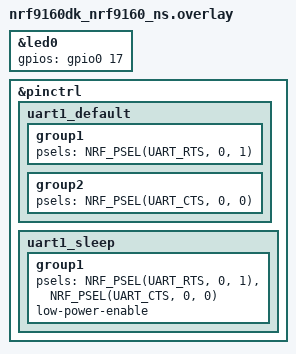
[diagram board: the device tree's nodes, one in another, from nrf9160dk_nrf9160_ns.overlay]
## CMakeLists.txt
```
#
# Copyright (c) 2020 Nordic Semiconductor
#
# SPDX-License-Identifier: LicenseRef-Nordic-5-Clause
#

cmake_minimum_required(VERSION 3.20.0)

find_package(Zephyr REQUIRED HINTS $ENV{ZEPHYR_BASE})
project(nrf9160-Recreation)

# NORDIC SDK APP START
target_sources(app PRIVATE src/main.c)
target_sources(app PRIVATE src/saadc.c)

# NORDIC SDK APP END

zephyr_include_directories(src)

# Make folder containing certificates global so that it can be located by
# the AWS IoT library.
zephyr_include_directories_ifdef(CONFIG_AWS_IOT_PROVISION_CERTIFICATES certs)

target_include_directories(app PRIVATE ../hal_nordic-master/nrfx/samples/common ../hal_nordic-master/nrfx/samples/src/nrfx_saadc/common)
```

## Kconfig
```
#
# Copyright (c) 2020 Nordic Semiconductor ASA
#
# SPDX-License-Identifier: LicenseRef-Nordic-5-Clause
#

menu "AWS IoT Sample Settings"

config AWS_IOT_SAMPLE_APP_VERSION
	string "Application version"
	default "v1.0.0"

config AWS_IOT_SAMPLE_PUBLICATION_INTERVAL_SECONDS
	int "Interval in seconds that the sample will publish data"
	default 15

config AWS_IOT_SAMPLE_CONNECTION_RETRY_TIMEOUT_SECONDS
	int "Number of seconds between each AWS IoT connection retry"
	default 30

config AWS_IOT_SAMPLE_DEVICE_ID_USE_HW_ID
	bool "Use HW ID as device ID"
	select HW_ID_LIBRARY
	help
	  Use the devices's hardware ID as device ID when connecting to AWS IOT

module = AWS_IOT_SAMPLE
module-str = AWS IoT sample
source "${ZEPHYR_BASE}/subsys/logging/Kconfig.template.log_config"

endmenu

menu "Zephyr Kernel"
source "Kconfig.zephyr"
endmenu
```

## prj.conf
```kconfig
#
# Copyright (c) 2020 Nordic Semiconductor ASA
#
# SPDX-License-Identifier: LicenseRef-Nordic-5-Clause
#
# General config
CONFIG_NCS_SAMPLES_DEFAULTS=y
CONFIG_REBOOT=y

# NEWLIB C
CONFIG_NEWLIB_LIBC=y
CONFIG_NEWLIB_LIBC_FLOAT_PRINTF=y

# Log
CONFIG_LOG=y
CONFIG_AWS_IOT_SAMPLE_LOG_LEVEL_INF=y
CONFIG_LOG_MODE_IMMEDIATE=y

# Network
CONFIG_NETWORKING=y
CONFIG_NET_NATIVE=n

# LTE link control
CONFIG_LTE_LINK_CONTROL=y
CONFIG_LTE_NETWORK_MODE_LTE_M=y

# Modem library
CONFIG_NRF_MODEM_LIB=y

# AT Host
CONFIG_UART_INTERRUPT_DRIVEN=y
CONFIG_AT_HOST_LIBRARY=y

# AWS IoT library
CONFIG_AWS_IOT=y
CONFIG_AWS_IOT_CLIENT_ID_STATIC="my-thing"
CONFIG_AWS_IOT_BROKER_HOST_NAME="a2eq7i1ma8qxed-ats.iot.us-east-2.amazonaws.com"
CONFIG_AWS_IOT_SEC_TAG=16842753
CONFIG_AWS_IOT_APP_SUBSCRIPTION_LIST_COUNT=2
CONFIG_AWS_IOT_TOPIC_UPDATE_DELTA_SUBSCRIBE=y
CONFIG_AWS_IOT_LAST_WILL=y
CONFIG_AWS_IOT_TOPIC_GET_ACCEPTED_SUBSCRIBE=y
CONFIG_AWS_IOT_TOPIC_GET_REJECTED_SUBSCRIBE=y

# MQTT - Maximum MQTT keepalive timeout specified by AWS IoT Core
CONFIG_MQTT_KEEPALIVE=1200

# Date Time library
CONFIG_DATE_TIME=y

# Modem information
CONFIG_MODEM_INFO=y

# Heap and stacks
CONFIG_HEAP_MEM_POOL_SIZE=8192
CONFIG_MAIN_STACK_SIZE=4096
CONFIG_SYSTEM_WORKQUEUE_STACK_SIZE=2048

# MCUBOOT
CONFIG_BOOTLOADER_MCUBOOT=y
CONFIG_MCUBOOT_IMG_MANAGER=y

# Image manager
CONFIG_IMG_MANAGER=y
CONFIG_STREAM_FLASH=y
CONFIG_FLASH_MAP=y
CONFIG_FLASH=y
CONFIG_IMG_ERASE_PROGRESSIVELY=y

# AWS FOTA
CONFIG_AWS_FOTA=y
CONFIG_FOTA_DOWNLOAD=y
CONFIG_DFU_TARGET=y

# CJSON
CONFIG_CJSON_LIB=y

# Download client (needed by AWS FOTA)
CONFIG_DOWNLOAD_CLIENT=y
CONFIG_DOWNLOAD_CLIENT_STACK_SIZE=4096

CONFIG_NRF_MODEM_LIB_TRACE=y
CONFIG_AT_HOST_LIBRARY=y #(note this is optional)

CONFIG_ADC=y
CONFIG_NRFX_GPIOTE=y
CONFIG_NRFX_SAADC=y
CONFIG_ASSERT=y
```

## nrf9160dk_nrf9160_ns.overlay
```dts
// To get started, press Ctrl+Space (or Option+Esc) to bring up the completion menu and view the available nodes.

// You can also use the buttons in the sidebar to perform actions on nodes.
// Actions currently available include:

// * Enabling / disabling the node
// * Adding the bus to a bus
// * Removing the node
// * Connecting ADC channels

// For more help, browse the DeviceTree documentation at https://docs.zephyrproject.org/latest/guides/dts/index.html
// You can also visit the nRF DeviceTree extension documentation at https://nrfconnect.github.io/vscode-nrf-connect/devicetree/nrfdevicetree.html
&led0 {
    gpios = <&gpio0 17 0 >;
};

&pinctrl {
    uart1_default {
        group1 {
            psels = <NRF_PSEL(UART_RTS, 0, 1)>;

        };
        group2 {
            psels = <NRF_PSEL(UART_CTS, 0, 0)>;
        };

    };

    uart1_sleep {
        group1 {
            psels = <NRF_PSEL(UART_RTS, 0, 1)>,
				<NRF_PSEL(UART_CTS, 0, 0)>; 
            low-power-enable;
        };
    };
};
```

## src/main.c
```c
/*
 * Copyright (c) 2020 Nordic Semiconductor ASA
 *
 * SPDX-License-Identifier: LicenseRef-Nordic-5-Clause
 */

#include <zephyr/kernel.h>
#include <stdio.h>
#include <stdlib.h>
#if defined(CONFIG_NRF_MODEM_LIB)
#include <modem/lte_lc.h>
#include <modem/nrf_modem_lib.h>
#include <modem/modem_info.h>
#include <nrf_modem.h>
#endif
#include <net/aws_iot.h>
#include <zephyr/sys/reboot.h>
#include <date_time.h>
#include <zephyr/dfu/mcuboot.h>
#include <cJSON.h>
#include <cJSON_os.h>
#include <zephyr/logging/log.h>
#if defined(CONFIG_AWS_IOT_SAMPLE_DEVICE_ID_USE_HW_ID)
#include <hw_id.h>
#endif

#define MAX_FLOAT_STR_SIZE 15

LOG_MODULE_REGISTER(aws_iot_sample, CONFIG_AWS_IOT_SAMPLE_LOG_LEVEL);

BUILD_ASSERT(!IS_ENABLED(CONFIG_LTE_AUTO_INIT_AND_CONNECT),
	     "This sample does not support LTE auto-init and connect");

#define APP_TOPICS_COUNT CONFIG_AWS_IOT_APP_SUBSCRIPTION_LIST_COUNT

static struct k_work_delayable shadow_update_work;
static struct k_work_delayable connect_work;
static struct k_work shadow_update_version_work;

static bool cloud_connected;

static K_SEM_DEFINE(lte_connected, 0, 1);
static K_SEM_DEFINE(date_time_obtained, 0, 1);

static int json_add_obj(cJSON *parent, const char *str, cJSON *item)
{
	cJSON_AddItemToObject(parent, str, item);

	return 0;
}

static int json_add_str(cJSON *parent, const char *str, const char *item)
{
	cJSON *json_str;

	json_str = cJSON_CreateString(item);
	if (json_str == NULL) {
		return -ENOMEM;
	}

	return json_add_obj(parent, str, json_str);
}

static int json_add_number(cJSON *parent, const char *str, double item)
{
	cJSON *json_num;

	json_num = cJSON_CreateNumber(item);
	if (json_num == NULL) {
		return -ENOMEM;
	}

	return json_add_obj(parent, str, json_num);
}

static int shadow_update(bool version_number_include)
{
	int err;
	char *message;
	int64_t message_ts = 0;
	float mV = 0;
	int raw = 0;

	LOG_INF("Getting date and time");
	err = date_time_now(&message_ts);
	if (err) {
		LOG_ERR("date_time_now, error: %d", err);
		return err;
	}
	LOG_INF("Trying to read from the ADC");
	err = get_adc_reading(&mV, &raw);
		if (err) {
		LOG_ERR("get_adc_reading, error: %d", err);
		return err;
	}
	char float_str[MAX_FLOAT_STR_SIZE];
	snprintf(float_str, MAX_FLOAT_STR_SIZE, "%f", mV);
	LOG_INF("Raw value == %d mV value == %s", raw, float_str);

	cJSON *root_obj = cJSON_CreateObject();
	cJSON *state_obj = cJSON_CreateObject();
	cJSON *reported_obj = cJSON_CreateObject();

	if (root_obj == NULL || state_obj == NULL || reported_obj == NULL) {
		cJSON_Delete(root_obj);
		cJSON_Delete(state_obj);
		cJSON_Delete(reported_obj);
		err = -ENOMEM;
		return err;
	}

	if (version_number_include) {
		err = json_add_str(reported_obj, "app_version", CONFIG_AWS_IOT_SAMPLE_APP_VERSION);
	} else {
		err = 0;
	}

	err += json_add_number(reported_obj, "raw", raw);
	err += json_add_number(reported_obj, "converted", mV);
	err += json_add_number(reported_obj, "ts", message_ts);
	err += json_add_obj(state_obj, "reported", reported_obj);
	err += json_add_obj(root_obj, "state", state_obj);

	if (err) {
		LOG_ERR("json_add, error: %d", err);
		goto cleanup;
	}

	message = cJSON_Print(root_obj);
	if (message == NULL) {
		LOG_ERR("cJSON_Print, error: returned NULL");
		err = -ENOMEM;
		goto cleanup;
	}

	struct aws_iot_data tx_data = {
		.qos = MQTT_QOS_0_AT_MOST_ONCE,
		.topic.type = AWS_IOT_SHADOW_TOPIC_UPDATE,
		.ptr = message,
		.len = strlen(message)
	};

	LOG_INF("Publishing: %s to AWS IoT broker", message);

	err = aws_iot_send(&tx_data);
	if (err) {
		LOG_ERR("aws_iot_send, error: %d", err);
	}

	cJSON_FreeString(message);

cleanup:

	cJSON_Delete(root_obj);

	return err;
}

static void connect_work_fn(struct k_work *work)
{
	int err;

	if (cloud_connected) {
		return;
	}

	err = aws_iot_connect(NULL);
	if (err) {
		LOG_ERR("aws_iot_connect, error: %d", err);
	}

	LOG_INF("Next connection retry in %d seconds",
		CONFIG_AWS_IOT_SAMPLE_CONNECTION_RETRY_TIMEOUT_SECONDS);

	k_work_schedule(&connect_work,
			K_SECONDS(CONFIG_AWS_IOT_SAMPLE_CONNECTION_RETRY_TIMEOUT_SECONDS));
}

static void shadow_update_work_fn(struct k_work *work)
{
	int err;

	if (!cloud_connected) {
		return;
	}

	err = shadow_update(false);
	if (err) {
		LOG_ERR("shadow_update, error: %d", err);
	}

	LOG_INF("Next data publication in %d seconds",
		CONFIG_AWS_IOT_SAMPLE_PUBLICATION_INTERVAL_SECONDS);

	k_work_schedule(&shadow_update_work,
			K_SECONDS(CONFIG_AWS_IOT_SAMPLE_PUBLICATION_INTERVAL_SECONDS));
}

static void shadow_update_version_work_fn(struct k_work *work)
{
	int err;

	err = shadow_update(true);
	if (err) {
		LOG_ERR("shadow_update, error: %d", err);
	}
}

static void print_received_data(const char *buf, const char *topic,
				size_t topic_len)
{
	char *str = NULL;
	cJSON *root_obj = NULL;

	root_obj = cJSON_Parse(buf);
	if (root_obj == NULL) {
		LOG_ERR("cJSON Parse failure");
		return;
	}

	str = cJSON_Print(root_obj);
	if (str == NULL) {
		LOG_ERR("Failed to print JSON object");
		goto clean_exit;
	}

	LOG_INF("Data received from AWS IoT console: Topic: %.*s Message: %s",
		topic_len, topic, str);

	cJSON_FreeString(str);

clean_exit:
	cJSON_Delete(root_obj);
}

void aws_iot_event_handler(const struct aws_iot_evt *const evt)
{
	switch (evt->type) {
	case AWS_IOT_EVT_CONNECTING:
		LOG_INF("AWS_IOT_EVT_CONNECTING");
		break;
	case AWS_IOT_EVT_CONNECTED:
		LOG_INF("AWS_IOT_EVT_CONNECTED");

		cloud_connected = true;
		/* This may fail if the work item is already being processed,
		 * but in such case, the next time the work handler is executed,
		 * it will exit after checking the above flag and the work will
		 * not be scheduled again.
		 */
		(void)k_work_cancel_delayable(&connect_work);

		if (evt->data.persistent_session) {
			LOG_INF("Persistent session enabled");
		}

#if defined(CONFIG_NRF_MODEM_LIB)
		/** Successfully connected to AWS IoT broker, mark image as
		 *  working to avoid reverting to the former image upon reboot.
		 */
		boot_write_img_confirmed();
#endif

		/** Send version number to AWS IoT broker to verify that the
		 *  FOTA update worked.
		 */
		k_work_submit(&shadow_update_version_work);

		/** Start sequential shadow data updates.
		 */
		k_work_schedule(&shadow_update_work,
				K_SECONDS(CONFIG_AWS_IOT_SAMPLE_PUBLICATION_INTERVAL_SECONDS));

#if defined(CONFIG_NRF_MODEM_LIB)
		int err = lte_lc_psm_req(true);
		if (err) {
			LOG_ERR("Requesting PSM failed, error: %d", err);
		}
#endif
		break;
	case AWS_IOT_EVT_READY:
		LOG_INF("AWS_IOT_EVT_READY");
		break;
	case AWS_IOT_EVT_DISCONNECTED:
		LOG_INF("AWS_IOT_EVT_DISCONNECTED");
		cloud_connected = false;
		/* This may fail if the work item is already being processed,
		 * but in such case, the next time the work handler is executed,
		 * it will exit after checking the above flag and the work will
		 * not be scheduled again.
		 */
		(void)k_work_cancel_delayable(&shadow_update_work);
		k_work_schedule(&connect_work, K_NO_WAIT);
		break;
	case AWS_IOT_EVT_DATA_RECEIVED:
		LOG_INF("AWS_IOT_EVT_DATA_RECEIVED");
		print_received_data(evt->data.msg.ptr, evt->data.msg.topic.str,
				    evt->data.msg.topic.len);
		break;
	case AWS_IOT_EVT_PUBACK:
		LOG_INF("AWS_IOT_EVT_PUBACK, message ID: %d", evt->data.message_id);
		break;
	case AWS_IOT_EVT_FOTA_START:
		LOG_INF("AWS_IOT_EVT_FOTA_START");
		break;
	case AWS_IOT_EVT_FOTA_ERASE_PENDING:
		LOG_INF("AWS_IOT_EVT_FOTA_ERASE_PENDING");
		LOG_INF("Disconnect LTE link or reboot");
#if defined(CONFIG_NRF_MODEM_LIB)
		err = lte_lc_offline();
		if (err) {
			LOG_ERR("Error disconnecting from LTE");
		}
#endif
		break;
	case AWS_IOT_EVT_FOTA_ERASE_DONE:
		LOG_INF("AWS_FOTA_EVT_ERASE_DONE");
		LOG_INF("Reconnecting the LTE link");
#if defined(CONFIG_NRF_MODEM_LIB)
		err = lte_lc_connect();
		if (err) {
			LOG_ERR("Error connecting to LTE");
		}
#endif
		break;
	case AWS_IOT_EVT_FOTA_DONE:
		LOG_INF("AWS_IOT_EVT_FOTA_DONE");
		LOG_INF("FOTA done, rebooting device");
		aws_iot_disconnect();
		sys_reboot(0);
		break;
	case AWS_IOT_EVT_FOTA_DL_PROGRESS:
		LOG_INF("AWS_IOT_EVT_FOTA_DL_PROGRESS, (%d%%)", evt->data.fota_progress);
	case AWS_IOT_EVT_ERROR:
		LOG_INF("AWS_IOT_EVT_ERROR, %d", evt->data.err);
		break;
	case AWS_IOT_EVT_FOTA_ERROR:
		LOG_INF("AWS_IOT_EVT_FOTA_ERROR");
		break;
	default:
		LOG_WRN("Unknown AWS IoT event type: %d", evt->type);
		break;
	}
}

static void work_init(void)
{
	k_work_init_delayable(&shadow_update_work, shadow_update_work_fn);
	k_work_init_delayable(&connect_work, connect_work_fn);
	k_work_init(&shadow_update_version_work, shadow_update_version_work_fn);
}

#if defined(CONFIG_NRF_MODEM_LIB)
static void lte_handler(const struct lte_lc_evt *const evt)
{
	switch (evt->type) {
	case LTE_LC_EVT_NW_REG_STATUS:
		if ((evt->nw_reg_status != LTE_LC_NW_REG_REGISTERED_HOME) &&
		     (evt->nw_reg_status != LTE_LC_NW_REG_REGISTERED_ROAMING)) {
			break;
		}

		LOG_INF("Network registration status: %s",
			evt->nw_reg_status == LTE_LC_NW_REG_REGISTERED_HOME ?
			"Connected - home network" : "Connected - roaming");

		k_sem_give(&lte_connected);
		break;
	case LTE_LC_EVT_PSM_UPDATE:
		LOG_INF("PSM parameter update: TAU: %d, Active time: %d",
			evt->psm_cfg.tau, evt->psm_cfg.active_time);
		break;
	case LTE_LC_EVT_EDRX_UPDATE: {
		char log_buf[60];
		ssize_t len;

		len = snprintf(log_buf, sizeof(log_buf),
			       "eDRX parameter update: eDRX: %f, PTW: %f",
			       evt->edrx_cfg.edrx, evt->edrx_cfg.ptw);
		if (len > 0) {
			LOG_INF("%s", log_buf);
		}
		break;
	}
	case LTE_LC_EVT_RRC_UPDATE:
		LOG_INF("RRC mode: %s",
			evt->rrc_mode == LTE_LC_RRC_MODE_CONNECTED ?
			"Connected" : "Idle");
		break;
	case LTE_LC_EVT_CELL_UPDATE:
		LOG_INF("LTE cell changed: Cell ID: %d, Tracking area: %d",
			evt->cell.id, evt->cell.tac);
		break;
	default:
		break;
	}
}

static void nrf_modem_lib_dfu_handler(int err)
{
	switch (err) {
	case NRF_MODEM_DFU_RESULT_OK:
		LOG_INF("Modem update suceeded, reboot");
		sys_reboot(SYS_REBOOT_COLD);
		break;
	case NRF_MODEM_DFU_RESULT_UUID_ERROR:
	case NRF_MODEM_DFU_RESULT_AUTH_ERROR:
		LOG_INF("Modem update failed, error: %d", err);
		LOG_INF("Modem will use old firmware");
		sys_reboot(SYS_REBOOT_COLD);
		break;
	case NRF_MODEM_DFU_RESULT_HARDWARE_ERROR:
	case NRF_MODEM_DFU_RESULT_INTERNAL_ERROR:
		LOG_INF("Modem update malfunction, error: %d, reboot", err);
		sys_reboot(SYS_REBOOT_COLD);
		break;
	case NRF_MODEM_DFU_RESULT_VOLTAGE_LOW:
		LOG_INF("Modem update cancelled due to low power, error: %d", err);
		LOG_INF("Please reboot once you have sufficient power for the DFU");
		break;
	default:
		break;
	}
}
#endif

static int app_topics_subscribe(void)
{
	int err;
	static char custom_topic[75] = "my-custom-topic/example";
	static char custom_topic_2[75] = "my-custom-topic/example_2";

	const struct aws_iot_topic_data topics_list[APP_TOPICS_COUNT] = {
		[0].str = custom_topic,
		[0].len = strlen(custom_topic),
		[1].str = custom_topic_2,
		[1].len = strlen(custom_topic_2)
	};

	err = aws_iot_subscription_topics_add(topics_list, ARRAY_SIZE(topics_list));
	if (err) {
		LOG_ERR("aws_iot_subscription_topics_add, error: %d", err);
	}

	return err;
}

static void date_time_event_handler(const struct date_time_evt *evt)
{
	switch (evt->type) {
	case DATE_TIME_OBTAINED_MODEM:
		/* Fall through */
	case DATE_TIME_OBTAINED_NTP:
		/* Fall through */
	case DATE_TIME_OBTAINED_EXT:
		LOG_INF("Date time obtained");
		k_sem_give(&date_time_obtained);

		/* De-register handler. At this point the sample will have
		 * date time to depend on indefinitely until a reboot occurs.
		 */
		date_time_register_handler(NULL);
		break;
	case DATE_TIME_NOT_OBTAINED:
		LOG_INF("DATE_TIME_NOT_OBTAINED");
		break;
	default:
		LOG_ERR("Unknown event: %d", evt->type);
		break;
	}
}

int main(void)
{
	int err;

	LOG_INF("The nRF9160 Recreation started");

	cJSON_Init();

#if defined(CONFIG_NRF_MODEM_LIB)
	err = nrf_modem_lib_init();
	if (err) {
		LOG_ERR("Modem library initialization failed, error: %d", err);
		return 0;
	}

	nrf_modem_lib_dfu_handler(err);
#endif

#if defined(CONFIG_AWS_IOT_SAMPLE_DEVICE_ID_USE_HW_ID)
	char device_id[HW_ID_LEN] = { 0 };

	err = hw_id_get(device_id, ARRAY_SIZE(device_id));
	if (err) {
		LOG_ERR("Failed to retrieve device ID, error: %d", err);
		return 0;
	}

	struct aws_iot_config config = {
	    .client_id = device_id,
	    .client_id_len = strlen(device_id)
	};

	LOG_INF("Device id: %s", device_id);

	err = aws_iot_init(&config, aws_iot_event_handler);
#else
	err = aws_iot_init(NULL, aws_iot_event_handler);
#endif
	if (err) {
		LOG_ERR("AWS IoT library could not be initialized, error: %d", err);
	}

	/** Subscribe to customizable non-shadow specific topics
	 *  to AWS IoT backend.
	 */
	err = app_topics_subscribe();
	if (err) {
		LOG_ERR("Adding application specific topics failed, error: %d", err);
	}

	work_init();
#if defined(CONFIG_NRF_MODEM_LIB)
	err = lte_lc_init_and_connect_async(lte_handler);
	if (err) {
		LOG_ERR("Modem could not be configured, error: %d", err);
		return 0;
	}

	err = modem_info_init();
	if (err) {
		LOG_ERR("Failed initializing modem info module, error: %d", err);
	}

	k_sem_take(&lte_connected, K_FOREVER);
#endif

	/* Trigger a date time update. The date_time API is used to timestamp data that is sent
	 * to AWS IoT.
	 */
	date_time_update_async(date_time_event_handler);

	/* Postpone connecting to AWS IoT until date time has been obtained. */
	k_sem_take(&date_time_obtained, K_FOREVER);
	k_work_schedule(&connect_work, K_NO_WAIT);

	return 0;
}
```

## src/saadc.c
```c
#include <zephyr/kernel.h>
#include <zephyr/device.h>
#include <zephyr/drivers/gpio.h>
#include <zephyr/drivers/adc.h>
#include <stdio.h>
#include <string.h>
#include <nrfx_saadc.h>
#include <nrfx_gpiote.h>
#include <nrfx_example.h>
#include <saadc_examples_common.h>
#include <nrfx_log.h>


#define ADC_1ST_CHANNEL_INPUT NRF_SAADC_INPUT_AIN1
#define BUFFER_SIZE 2UL
#define SAMPLING_ITERATIONS 4UL
#define ADC_RESOLUTION NRF_SAADC_RESOLUTION_14BIT
#define ADC_GAIN ADC_GAIN_1_4
#define ADC_REFERENCE ADC_REF_VDD_1_4
#define ADC_ACQUISITION_TIME ADC_ACQ_TIME(ADC_ACQ_TIME_MICROSECONDS, 20)
#define SLEEP_TIME_MS 700
#define ADC_OVERSAMPLING SAADC_OVERSAMPLE_OVERSAMPLE_Over256x
#define VDD_GPIO 1800

static nrf_saadc_value_t m_samples_buffer[BUFFER_SIZE];

float custom_raw_to_milli(int raw) {
	//Hard coded values, change with Gain/Resolution Stuff
    float denominator = 0.00055556;  //.25/VDD_4
    int exponent = 16384; //2^RESOLUTION

    // Calculate [V(P) - V(N)]
    float voltageDifference = (raw / (denominator * exponent));

    return voltageDifference;
}

static const nrfx_saadc_channel_t nrf_1st_channel = {
	.channel_config = {
		.resistor_p = NRF_SAADC_RESISTOR_DISABLED,
		.resistor_n = NRF_SAADC_RESISTOR_DISABLED,
		.gain = ADC_GAIN,
		.reference = ADC_REFERENCE,
		.acq_time = ADC_ACQUISITION_TIME,
		.mode = NRF_SAADC_MODE_SINGLE_ENDED,
		.burst = NRF_SAADC_BURST_ENABLED,
	},
	.pin_p = ADC_1ST_CHANNEL_INPUT,
	.pin_n = NRF_SAADC_INPUT_DISABLED,
	.channel_index = 0
};

int get_adc_reading(float *milivolt, int *raw) {

	struct gpio_dt_spec p17 = GPIO_DT_SPEC_GET(DT_NODELABEL(led0), gpios);
	struct gpio_dt_spec led1 = GPIO_DT_SPEC_GET(DT_ALIAS(led1), gpios);

	if (!device_is_ready(p17.port)) return -1;
	if (!device_is_ready(led1.port)) return -1;

	nrfx_err_t status;
    (void)status;

	status = nrfx_saadc_init(NRFX_SAADC_DEFAULT_CONFIG_IRQ_PRIORITY);
    NRFX_ASSERT(status == NRFX_SUCCESS);


    status = nrfx_saadc_channel_config(&nrf_1st_channel);
    NRFX_ASSERT(status == NRFX_SUCCESS);

	nrfx_saadc_adv_config_t nrf_adv_1st_cfg = {
		.oversampling = ADC_OVERSAMPLING,
		.burst = NRF_SAADC_BURST_ENABLED,
	};

	uint32_t channel_mask = nrfx_saadc_channels_configured_get();
    status = nrfx_saadc_advanced_mode_set(channel_mask,
                                          ADC_RESOLUTION,
                                          &nrf_adv_1st_cfg,
                                          NULL);
    NRFX_ASSERT(status == NRFX_SUCCESS);

    status = nrfx_saadc_buffer_set(m_samples_buffer, BUFFER_SIZE);
    NRFX_ASSERT(status == NRFX_SUCCESS);

	status = nrfx_saadc_offset_calibrate(NULL);
	NRFX_ASSERT(status == NRFX_SUCCESS);
	printk("Calibration in the blocking manner finished successfully.\n");
	
	int err;
	gpio_pin_configure_dt(&p17, GPIO_OUTPUT);
	gpio_pin_configure_dt(&led1, GPIO_OUTPUT_ACTIVE);
	err = gpio_pin_set_dt(&p17, 1);
	err = gpio_pin_set_dt(&led1, 1);

	if (err) return err;
	
	int ret = 0;
	float adc_voltage = 0;

	while ((status = nrfx_saadc_mode_trigger()) == NRFX_ERROR_BUSY)
	{}
	NRFX_ASSERT(status == NRFX_SUCCESS);
	adc_voltage = m_samples_buffer[1];
	adc_voltage = custom_raw_to_milli(adc_voltage);

	*raw = m_samples_buffer[1];
	*milivolt = adc_voltage;	

	nrfx_saadc_uninit();
	
	gpio_pin_set_dt(&p17, 0);
	gpio_pin_set_dt(&led1, 0);

	return 0;
}
```
